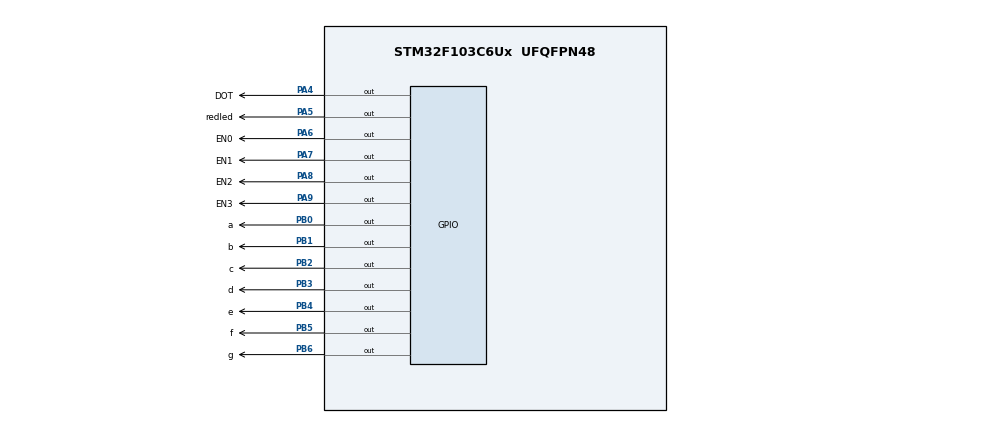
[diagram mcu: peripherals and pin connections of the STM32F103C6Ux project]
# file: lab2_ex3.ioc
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Mcu.Family=STM32F1
Mcu.Name=STM32F103C6Ux
Mcu.Package=UFQFPN48
NVIC.PriorityGroup=NVIC_PRIORITYGROUP_4
NVIC.TIM2_IRQn=true\:0\:0\:false\:false\:true\:true\:true
PA4.GPIO_Label=DOT
PA4.Signal=GPIO_Output
PA5.GPIO_Label=redled
PA5.Signal=GPIO_Output
PA6.GPIO_Label=EN0
PA6.Signal=GPIO_Output
PA7.GPIO_Label=EN1
PA7.Signal=GPIO_Output
PA8.GPIO_Label=EN2
PA8.Signal=GPIO_Output
PA9.GPIO_Label=EN3
PA9.Signal=GPIO_Output
PB0.GPIO_Label=a
PB0.Signal=GPIO_Output
PB1.GPIO_Label=b
PB1.Signal=GPIO_Output
PB2.GPIO_Label=c
PB2.Signal=GPIO_Output
PB3.GPIO_Label=d
PB3.Signal=GPIO_Output
PB4.GPIO_Label=e
PB4.Signal=GPIO_Output
PB5.GPIO_Label=f
PB5.Signal=GPIO_Output
PB6.GPIO_Label=g
PB6.Signal=GPIO_Output
ProjectManager.HeapSize=0x200
ProjectManager.StackSize=0x400
ProjectManager.TargetToolchain=STM32CubeIDE
RCC.APB1Freq_Value=8000000
RCC.APB2Freq_Value=8000000
TIM2.Period=9
TIM2.Prescaler=7999
VP_SYS_VS_ND.Mode=No_Debug
VP_TIM2_VS_ClockSourceINT.Mode=Internal
board=custom

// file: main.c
/* USER CODE BEGIN Header */
/**
  ******************************************************************************
  * @file           : main.c
  * @brief          : Main program body
  ******************************************************************************
  * @attention
  *
  * <h2><center>&copy; Copyright (c) 2025 STMicroelectronics.
  * All rights reserved.</center></h2>
  *
  * This software component is licensed by ST under BSD 3-Clause license,
  * the "License"; You may not use this file except in compliance with the
  * License. You may obtain a copy of the License at:
  *                        opensource.org/licenses/BSD-3-Clause
  *
  ******************************************************************************
  */
/* USER CODE END Header */
#include "main.h"

/* USER CODE BEGIN Includes */
#include "software_timer.h"
/* USER CODE END Includes */

TIM_HandleTypeDef htim2;

void SystemClock_Config(void);
static void MX_GPIO_Init(void);
static void MX_TIM2_Init(void);

int main(void)
{

  /* MCU Configuration--------------------------------------------------------*/

  /* Reset of all peripherals, Initializes the Flash interface and the Systick. */
  HAL_Init();

  /* Configure the system clock */
  SystemClock_Config();

  /* Initialize all configured peripherals */
  MX_GPIO_Init();
  MX_TIM2_Init();
  /* USER CODE BEGIN 2 */
  HAL_TIM_Base_Start_IT (& htim2 );
  /* USER CODE END 2 */

  const int MAX_LED = 4;
  int index_led = 0;
  int led_buffer[4] = {1, 2, 3, 4};

	  void display7SEG(int num) {
	      switch (num) {
	      case 0:
	          HAL_GPIO_WritePin(a_GPIO_Port, a_Pin, GPIO_PIN_RESET);
	          HAL_GPIO_WritePin(b_GPIO_Port, b_Pin, GPIO_PIN_RESET);
	          HAL_GPIO_WritePin(c_GPIO_Port, c_Pin, GPIO_PIN_RESET);
	          HAL_GPIO_WritePin(d_GPIO_Port, d_Pin, GPIO_PIN_RESET);
	          HAL_GPIO_WritePin(e_GPIO_Port, e_Pin, GPIO_PIN_RESET);
	          HAL_GPIO_WritePin(f_GPIO_Port, f_Pin, GPIO_PIN_RESET);
	          HAL_GPIO_WritePin(g_GPIO_Port, g_Pin, GPIO_PIN_SET);
	          break;
	      case 1:
	          HAL_GPIO_WritePin(a_GPIO_Port, a_Pin, GPIO_PIN_SET);
	          HAL_GPIO_WritePin(b_GPIO_Port, b_Pin, GPIO_PIN_RESET);
	          HAL_GPIO_WritePin(c_GPIO_Port, c_Pin, GPIO_PIN_RESET);
	          HAL_GPIO_WritePin(d_GPIO_Port, d_Pin, GPIO_PIN_SET);
	          HAL_GPIO_WritePin(e_GPIO_Port, e_Pin, GPIO_PIN_SET);
	          HAL_GPIO_WritePin(f_GPIO_Port, f_Pin, GPIO_PIN_SET);
	          HAL_GPIO_WritePin(g_GPIO_Port, g_Pin, GPIO_PIN_SET);
	          break;
	      case 2:
	          HAL_GPIO_WritePin(a_GPIO_Port, a_Pin, GPIO_PIN_RESET);
	          HAL_GPIO_WritePin(b_GPIO_Port, b_Pin, GPIO_PIN_RESET);
	          HAL_GPIO_WritePin(c_GPIO_Port, c_Pin, GPIO_PIN_SET);
	          HAL_GPIO_WritePin(d_GPIO_Port, d_Pin, GPIO_PIN_RESET);
	          HAL_GPIO_WritePin(e_GPIO_Port, e_Pin, GPIO_PIN_RESET);
	          HAL_GPIO_WritePin(f_GPIO_Port, f_Pin, GPIO_PIN_SET);
	          HAL_GPIO_WritePin(g_GPIO_Port, g_Pin, GPIO_PIN_RESET);
	          break;
	      case 3:
	          HAL_GPIO_WritePin(a_GPIO_Port, a_Pin, GPIO_PIN_RESET);
	          HAL_GPIO_WritePin(b_GPIO_Port, b_Pin, GPIO_PIN_RESET);
	          HAL_GPIO_WritePin(c_GPIO_Port, c_Pin, GPIO_PIN_RESET);
	          HAL_GPIO_WritePin(d_GPIO_Port, d_Pin, GPIO_PIN_RESET);
	          HAL_GPIO_WritePin(e_GPIO_Port, e_Pin, GPIO_PIN_SET);
	          HAL_GPIO_WritePin(f_GPIO_Port, f_Pin, GPIO_PIN_SET);
	          HAL_GPIO_WritePin(g_GPIO_Port, g_Pin, GPIO_PIN_RESET);
	          break;
	      case 4:
	          HAL_GPIO_WritePin(a_GPIO_Port, a_Pin, GPIO_PIN_SET);
	          HAL_GPIO_WritePin(b_GPIO_Port, b_Pin, GPIO_PIN_RESET);
	          HAL_GPIO_WritePin(c_GPIO_Port, c_Pin, GPIO_PIN_RESET);
	          HAL_GPIO_WritePin(d_GPIO_Port, d_Pin, GPIO_PIN_SET);
	          HAL_GPIO_WritePin(e_GPIO_Port, e_Pin, GPIO_PIN_SET);
	          HAL_GPIO_WritePin(f_GPIO_Port, f_Pin, GPIO_PIN_RESET);
	          HAL_GPIO_WritePin(g_GPIO_Port, g_Pin, GPIO_PIN_RESET);
	          break;
	      case 5:
	          HAL_GPIO_WritePin(a_GPIO_Port, a_Pin, GPIO_PIN_RESET);
	          HAL_GPIO_WritePin(b_GPIO_Port, b_Pin, GPIO_PIN_SET);
	          HAL_GPIO_WritePin(c_GPIO_Port, c_Pin, GPIO_PIN_RESET);
	          HAL_GPIO_WritePin(d_GPIO_Port, d_Pin, GPIO_PIN_RESET);
	          HAL_GPIO_WritePin(e_GPIO_Port, e_Pin, GPIO_PIN_SET);
	          HAL_GPIO_WritePin(f_GPIO_Port, f_Pin, GPIO_PIN_RESET);
	          HAL_GPIO_WritePin(g_GPIO_Port, g_Pin, GPIO_PIN_RESET);
	          break;
	      case 6:
	          HAL_GPIO_WritePin(a_GPIO_Port, a_Pin, GPIO_PIN_RESET);
	          HAL_GPIO_WritePin(b_GPIO_Port, b_Pin, GPIO_PIN_SET);
	          HAL_GPIO_WritePin(c_GPIO_Port, c_Pin, GPIO_PIN_RESET);
	          HAL_GPIO_WritePin(d_GPIO_Port, d_Pin, GPIO_PIN_RESET);
	          HAL_GPIO_WritePin(e_GPIO_Port, e_Pin, GPIO_PIN_RESET);
	          HAL_GPIO_WritePin(f_GPIO_Port, f_Pin, GPIO_PIN_RESET);
	          HAL_GPIO_WritePin(g_GPIO_Port, g_Pin, GPIO_PIN_RESET);
	          break;
	      case 7:
	          HAL_GPIO_WritePin(a_GPIO_Port, a_Pin, GPIO_PIN_RESET);
	          HAL_GPIO_WritePin(b_GPIO_Port, b_Pin, GPIO_PIN_RESET);
	          HAL_GPIO_WritePin(c_GPIO_Port, c_Pin, GPIO_PIN_RESET);
	          HAL_GPIO_WritePin(d_GPIO_Port, d_Pin, GPIO_PIN_SET);
	          HAL_GPIO_WritePin(e_GPIO_Port, e_Pin, GPIO_PIN_SET);
	          HAL_GPIO_WritePin(f_GPIO_Port, f_Pin, GPIO_PIN_SET);
	          HAL_GPIO_WritePin(g_GPIO_Port, g_Pin, GPIO_PIN_SET);
	          break;
	      case 8:
	          HAL_GPIO_WritePin(a_GPIO_Port, a_Pin, GPIO_PIN_RESET);
	          HAL_GPIO_WritePin(b_GPIO_Port, b_Pin, GPIO_PIN_RESET);
	          HAL_GPIO_WritePin(c_GPIO_Port, c_Pin, GPIO_PIN_RESET);
	          HAL_GPIO_WritePin(d_GPIO_Port, d_Pin, GPIO_PIN_RESET);
	          HAL_GPIO_WritePin(e_GPIO_Port, e_Pin, GPIO_PIN_RESET);
	          HAL_GPIO_WritePin(f_GPIO_Port, f_Pin, GPIO_PIN_RESET);
	          HAL_GPIO_WritePin(g_GPIO_Port, g_Pin, GPIO_PIN_RESET);
	          break;
	      case 9:
	          HAL_GPIO_WritePin(a_GPIO_Port, a_Pin, GPIO_PIN_RESET);
	          HAL_GPIO_WritePin(b_GPIO_Port, b_Pin, GPIO_PIN_RESET);
	          HAL_GPIO_WritePin(c_GPIO_Port, c_Pin, GPIO_PIN_RESET);
	          HAL_GPIO_WritePin(d_GPIO_Port, d_Pin, GPIO_PIN_RESET);
	          HAL_GPIO_WritePin(e_GPIO_Port, e_Pin, GPIO_PIN_SET);
	          HAL_GPIO_WritePin(f_GPIO_Port, f_Pin, GPIO_PIN_RESET);
	          HAL_GPIO_WritePin(g_GPIO_Port, g_Pin, GPIO_PIN_RESET);
	          break;
	      default:
	          HAL_GPIO_WritePin(a_GPIO_Port, a_Pin, GPIO_PIN_SET);
	          HAL_GPIO_WritePin(b_GPIO_Port, b_Pin, GPIO_PIN_SET);
	          HAL_GPIO_WritePin(c_GPIO_Port, c_Pin, GPIO_PIN_SET);
	          HAL_GPIO_WritePin(d_GPIO_Port, d_Pin, GPIO_PIN_SET);
	          HAL_GPIO_WritePin(e_GPIO_Port, e_Pin, GPIO_PIN_SET);
	          HAL_GPIO_WritePin(f_GPIO_Port, f_Pin, GPIO_PIN_SET);
	          HAL_GPIO_WritePin(g_GPIO_Port, g_Pin, GPIO_PIN_SET);
	          break;
	      }
  }

  void update7SEG(int index) {
	  HAL_GPIO_WritePin(EN0_GPIO_Port, EN0_Pin, GPIO_PIN_SET);
	      HAL_GPIO_WritePin(EN1_GPIO_Port, EN1_Pin, GPIO_PIN_SET);
	      HAL_GPIO_WritePin(EN2_GPIO_Port, EN2_Pin, GPIO_PIN_SET);
	      HAL_GPIO_WritePin(EN3_GPIO_Port, EN3_Pin, GPIO_PIN_SET);
      switch (index) {
      case 0:
             HAL_GPIO_WritePin(EN0_GPIO_Port, EN0_Pin, GPIO_PIN_RESET);
             display7SEG(led_buffer[0]);
             break;
         case 1:
             HAL_GPIO_WritePin(EN1_GPIO_Port, EN1_Pin, GPIO_PIN_RESET);
             display7SEG(led_buffer[1]);
             break;
         case 2:
             HAL_GPIO_WritePin(EN2_GPIO_Port, EN2_Pin, GPIO_PIN_RESET);
             display7SEG(led_buffer[2]);
             break;
         case 3:
             HAL_GPIO_WritePin(EN3_GPIO_Port, EN3_Pin, GPIO_PIN_RESET);
             display7SEG(led_buffer[3]);
             break;
         default:
             break;
      }
  }
  /* Infinite loop */
  /* USER CODE BEGIN WHILE */
setTimer1(100);
setTimer2(50);
  while (1)
  {
    /* USER CODE END WHILE */
if ( timer1_flag == 1 ) {
	HAL_GPIO_TogglePin(redled_GPIO_Port, redled_Pin);
		HAL_GPIO_TogglePin(DOT_GPIO_Port, DOT_Pin);
		setTimer1(100);
}

if ( timer2_flag == 1) {
	update7SEG(index_led++);
	if (index_led >= MAX_LED) index_led = 0;
	setTimer2(50);
}
  }
}

void SystemClock_Config(void)
{
  RCC_OscInitTypeDef RCC_OscInitStruct = {0};
  RCC_ClkInitTypeDef RCC_ClkInitStruct = {0};

  /** Initializes the RCC Oscillators according to the specified parameters
  * in the RCC_OscInitTypeDef structure.
  */
  RCC_OscInitStruct.OscillatorType = RCC_OSCILLATORTYPE_HSI;
  RCC_OscInitStruct.HSIState = RCC_HSI_ON;
  RCC_OscInitStruct.HSICalibrationValue = RCC_HSICALIBRATION_DEFAULT;
  RCC_OscInitStruct.PLL.PLLState = RCC_PLL_NONE;
  if (HAL_RCC_OscConfig(&RCC_OscInitStruct) != HAL_OK)
  {
    Error_Handler();
  }
  /** Initializes the CPU, AHB and APB buses clocks
  */
  RCC_ClkInitStruct.ClockType = RCC_CLOCKTYPE_HCLK|RCC_CLOCKTYPE_SYSCLK
                              |RCC_CLOCKTYPE_PCLK1|RCC_CLOCKTYPE_PCLK2;
  RCC_ClkInitStruct.SYSCLKSource = RCC_SYSCLKSOURCE_HSI;
  RCC_ClkInitStruct.AHBCLKDivider = RCC_SYSCLK_DIV1;
  RCC_ClkInitStruct.APB1CLKDivider = RCC_HCLK_DIV1;
  RCC_ClkInitStruct.APB2CLKDivider = RCC_HCLK_DIV1;

  if (HAL_RCC_ClockConfig(&RCC_ClkInitStruct, FLASH_LATENCY_0) != HAL_OK)
  {
    Error_Handler();
  }
}

static void MX_TIM2_Init(void)
{

  TIM_ClockConfigTypeDef sClockSourceConfig = {0};
  TIM_MasterConfigTypeDef sMasterConfig = {0};

  htim2.Instance = TIM2;
  htim2.Init.Prescaler = 7999;
  htim2.Init.CounterMode = TIM_COUNTERMODE_UP;
  htim2.Init.Period = 9;
  htim2.Init.ClockDivision = TIM_CLOCKDIVISION_DIV1;
  htim2.Init.AutoReloadPreload = TIM_AUTORELOAD_PRELOAD_DISABLE;
  if (HAL_TIM_Base_Init(&htim2) != HAL_OK)
  {
    Error_Handler();
  }
  sClockSourceConfig.ClockSource = TIM_CLOCKSOURCE_INTERNAL;
  if (HAL_TIM_ConfigClockSource(&htim2, &sClockSourceConfig) != HAL_OK)
  {
    Error_Handler();
  }
  sMasterConfig.MasterOutputTrigger = TIM_TRGO_RESET;
  sMasterConfig.MasterSlaveMode = TIM_MASTERSLAVEMODE_DISABLE;
  if (HAL_TIMEx_MasterConfigSynchronization(&htim2, &sMasterConfig) != HAL_OK)
  {
    Error_Handler();
  }

}

static void MX_GPIO_Init(void)
{
  GPIO_InitTypeDef GPIO_InitStruct = {0};

  /* GPIO Ports Clock Enable */
  __HAL_RCC_GPIOA_CLK_ENABLE();
  __HAL_RCC_GPIOB_CLK_ENABLE();

  /*Configure GPIO pin Output Level */
  HAL_GPIO_WritePin(GPIOA, DOT_Pin|redled_Pin|EN0_Pin|EN1_Pin
                          |EN2_Pin|EN3_Pin, GPIO_PIN_RESET);

  /*Configure GPIO pin Output Level */
  HAL_GPIO_WritePin(GPIOB, a_Pin|b_Pin|c_Pin|d_Pin
                          |e_Pin|f_Pin|g_Pin, GPIO_PIN_RESET);

  /*Configure GPIO pins : DOT_Pin redled_Pin EN0_Pin EN1_Pin
                           EN2_Pin EN3_Pin */
  GPIO_InitStruct.Pin = DOT_Pin|redled_Pin|EN0_Pin|EN1_Pin
                          |EN2_Pin|EN3_Pin;
  GPIO_InitStruct.Mode = GPIO_MODE_OUTPUT_PP;
  GPIO_InitStruct.Pull = GPIO_NOPULL;
  GPIO_InitStruct.Speed = GPIO_SPEED_FREQ_LOW;
  HAL_GPIO_Init(GPIOA, &GPIO_InitStruct);

  /*Configure GPIO pins : a_Pin b_Pin c_Pin d_Pin
                           e_Pin f_Pin g_Pin */
  GPIO_InitStruct.Pin = a_Pin|b_Pin|c_Pin|d_Pin
                          |e_Pin|f_Pin|g_Pin;
  GPIO_InitStruct.Mode = GPIO_MODE_OUTPUT_PP;
  GPIO_InitStruct.Pull = GPIO_NOPULL;
  GPIO_InitStruct.Speed = GPIO_SPEED_FREQ_LOW;
  HAL_GPIO_Init(GPIOB, &GPIO_InitStruct);

}

/* USER CODE BEGIN 4 */
void HAL_TIM_PeriodElapsedCallback(TIM_HandleTypeDef *htim) {
	timerRun();
}
/* USER CODE END 4 */

void Error_Handler(void)
{
  __disable_irq();
  while (1)
  {
  }
}

/************************ (C) COPYRIGHT STMicroelectronics *****END OF FILE****/
